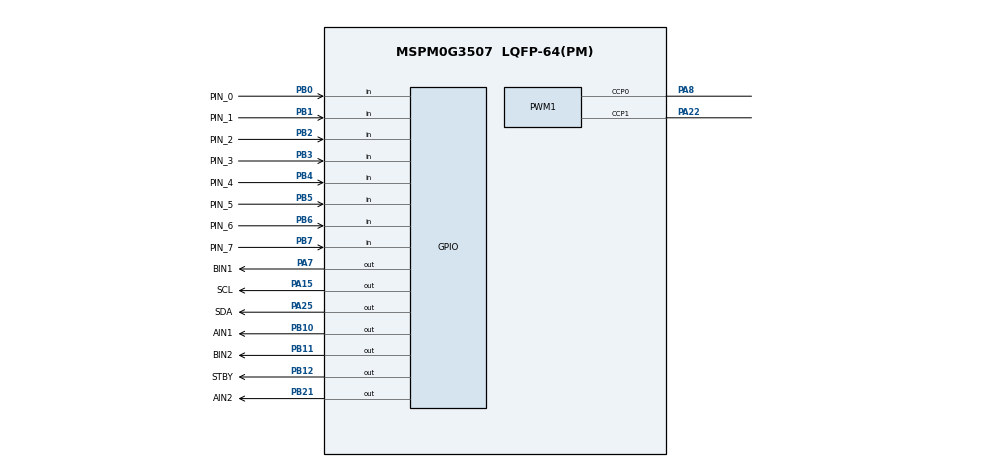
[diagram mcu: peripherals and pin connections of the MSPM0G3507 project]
/**
 * These arguments were used when this file was generated. They will be automatically applied on subsequent loads
 * via the GUI or CLI. Run CLI with '--help' for additional information on how to override these arguments.
 * @cliArgs --device "MSPM0G350X" --part "Default" --package "LQFP-64(PM)" --product "mspm0_sdk@2.08.00.03"
 * @v2CliArgs --device "MSPM0G3507" --package "LQFP-64(PM)" --product "mspm0_sdk@2.08.00.03"
 * @versions {"tool":"1.24.0+4110"}
 */

/**
 * Import the modules used in this configuration.
 */
const GPIO          = scripting.addModule("/ti/driverlib/GPIO", {}, false);
const GPIO1         = GPIO.addInstance();
const GPIO2         = GPIO.addInstance();
const GPIO3         = GPIO.addInstance();
const GPIO4         = GPIO.addInstance();
const GPIO5         = GPIO.addInstance();
const PWM           = scripting.addModule("/ti/driverlib/PWM", {}, false);
const PWM1          = PWM.addInstance();
const SYSCTL        = scripting.addModule("/ti/driverlib/SYSCTL");
const SYSTICK       = scripting.addModule("/ti/driverlib/SYSTICK");
const TIMER         = scripting.addModule("/ti/driverlib/TIMER", {}, false);
const TIMER1        = TIMER.addInstance();
const TIMER2        = TIMER.addInstance();
const ProjectConfig = scripting.addModule("/ti/project_config/ProjectConfig");

/**
 * Write custom configuration values to the imported modules.
 */
const divider7       = system.clockTree["PLL_PDIV"];
divider7.divideValue = 2;

const divider9       = system.clockTree["UDIV"];
divider9.divideValue = 2;

const gate7  = system.clockTree["MFCLKGATE"];
gate7.enable = true;

const multiplier2         = system.clockTree["PLL_QDIV"];
multiplier2.multiplyValue = 8;

const mux4       = system.clockTree["EXHFMUX"];
mux4.inputSelect = "EXHFMUX_XTAL";

const mux8       = system.clockTree["HSCLKMUX"];
mux8.inputSelect = "HSCLKMUX_SYSPLL0";

const mux12       = system.clockTree["SYSPLLMUX"];
mux12.inputSelect = "zSYSPLLMUX_HFCLK";

const pinFunction4        = system.clockTree["HFXT"];
pinFunction4.inputFreq    = 40;
pinFunction4.enable       = true;
pinFunction4.HFCLKMonitor = true;
pinFunction4.HFXTStartup  = 100;

GPIO1.$name                          = "OLED";
GPIO1.port                           = "PORTA";
GPIO1.associatedPins.create(2);
GPIO1.associatedPins[0].$name        = "SCL";
GPIO1.associatedPins[0].initialValue = "SET";
GPIO1.associatedPins[0].assignedPin  = "15";
GPIO1.associatedPins[0].ioStructure  = "SD";
GPIO1.associatedPins[0].pin.$assign  = "PA15";
GPIO1.associatedPins[1].$name        = "SDA";
GPIO1.associatedPins[1].initialValue = "SET";
GPIO1.associatedPins[1].assignedPin  = "25";
GPIO1.associatedPins[1].ioStructure  = "SD";
GPIO1.associatedPins[1].pin.$assign  = "PA25";

const Board = scripting.addModule("/ti/driverlib/Board", {}, false);

GPIO2.$name                              = "LS";
GPIO2.port                               = "PORTB";
GPIO2.associatedPins.create(8);
GPIO2.associatedPins[0].$name            = "PIN_0";
GPIO2.associatedPins[0].direction        = "INPUT";
GPIO2.associatedPins[0].internalResistor = "PULL_UP";
GPIO2.associatedPins[0].ioStructure      = "SD";
GPIO2.associatedPins[0].assignedPin      = "0";
GPIO2.associatedPins[0].pin.$assign      = "PB0";
GPIO2.associatedPins[1].$name            = "PIN_1";
GPIO2.associatedPins[1].direction        = "INPUT";
GPIO2.associatedPins[1].ioStructure      = "SD";
GPIO2.associatedPins[1].internalResistor = "PULL_UP";
GPIO2.associatedPins[1].assignedPin      = "1";
GPIO2.associatedPins[1].pin.$assign      = "PB1";
GPIO2.associatedPins[2].$name            = "PIN_2";
GPIO2.associatedPins[2].direction        = "INPUT";
GPIO2.associatedPins[2].ioStructure      = "SD";
GPIO2.associatedPins[2].internalResistor = "PULL_UP";
GPIO2.associatedPins[2].assignedPin      = "2";
GPIO2.associatedPins[2].pin.$assign      = "PB2";
GPIO2.associatedPins[3].$name            = "PIN_3";
GPIO2.associatedPins[3].direction        = "INPUT";
GPIO2.associatedPins[3].ioStructure      = "SD";
GPIO2.associatedPins[3].internalResistor = "PULL_UP";
GPIO2.associatedPins[3].assignedPin      = "3";
GPIO2.associatedPins[3].pin.$assign      = "PB3";
GPIO2.associatedPins[4].$name            = "PIN_4";
GPIO2.associatedPins[4].direction        = "INPUT";
GPIO2.associatedPins[4].ioStructure      = "SD";
GPIO2.associatedPins[4].internalResistor = "PULL_UP";
GPIO2.associatedPins[4].assignedPin      = "4";
GPIO2.associatedPins[4].pin.$assign      = "PB4";
GPIO2.associatedPins[5].$name            = "PIN_5";
GPIO2.associatedPins[5].direction        = "INPUT";
GPIO2.associatedPins[5].ioStructure      = "SD";
GPIO2.associatedPins[5].internalResistor = "PULL_UP";
GPIO2.associatedPins[5].assignedPin      = "5";
GPIO2.associatedPins[5].pin.$assign      = "PB5";
GPIO2.associatedPins[6].$name            = "PIN_6";
GPIO2.associatedPins[6].direction        = "INPUT";
GPIO2.associatedPins[6].ioStructure      = "SD";
GPIO2.associatedPins[6].internalResistor = "PULL_UP";
GPIO2.associatedPins[6].assignedPin      = "6";
GPIO2.associatedPins[6].pin.$assign      = "PB6";
GPIO2.associatedPins[7].$name            = "PIN_7";
GPIO2.associatedPins[7].direction        = "INPUT";
GPIO2.associatedPins[7].ioStructure      = "SD";
GPIO2.associatedPins[7].internalResistor = "PULL_UP";
GPIO2.associatedPins[7].assignedPin      = "7";
GPIO2.associatedPins[7].pin.$assign      = "PB7";

GPIO3.$name                              = "PWM";
GPIO3.associatedPins.create(5);
GPIO3.associatedPins[0].$name            = "AIN1";
GPIO3.associatedPins[0].ioStructure      = "SD";
GPIO3.associatedPins[0].pin.$assign      = "PB10";
GPIO3.associatedPins[1].$name            = "AIN2";
GPIO3.associatedPins[1].ioStructure      = "SD";
GPIO3.associatedPins[1].pin.$assign      = "PB21";
GPIO3.associatedPins[2].$name            = "BIN1";
GPIO3.associatedPins[2].ioStructure      = "SD";
GPIO3.associatedPins[2].pin.$assign      = "PA7";
GPIO3.associatedPins[3].$name            = "BIN2";
GPIO3.associatedPins[3].ioStructure      = "SD";
GPIO3.associatedPins[3].pin.$assign      = "PB11";
GPIO3.associatedPins[4].$name            = "STBY";
GPIO3.associatedPins[4].ioStructure      = "SD";
GPIO3.associatedPins[4].internalResistor = "PULL_UP";
GPIO3.associatedPins[4].pin.$assign      = "PB12";

GPIO4.$name                               = "GPIO_ENCODER_L";
GPIO4.associatedPins.create(2);
GPIO4.associatedPins[0].direction         = "INPUT";
GPIO4.associatedPins[0].polarity          = "RISE";
GPIO4.associatedPins[0].interruptPriority = "0";
GPIO4.associatedPins[0].assignedPort      = "PORTA";
GPIO4.associatedPins[0].$name             = "E1A";
GPIO4.associatedPins[0].assignedPin       = "12";
GPIO4.associatedPins[1].direction         = "INPUT";
GPIO4.associatedPins[1].assignedPort      = "PORTB";
GPIO4.associatedPins[1].assignedPin       = "22";
GPIO4.associatedPins[1].polarity          = "RISE";
GPIO4.associatedPins[1].interruptEn       = true;
GPIO4.associatedPins[1].interruptPriority = "0";
GPIO4.associatedPins[1].$name             = "E1B";

GPIO5.$name                               = "GPIO_ENCODER_R";
GPIO5.associatedPins.create(2);
GPIO5.associatedPins[0].direction         = "INPUT";
GPIO5.associatedPins[0].assignedPort      = "PORTB";
GPIO5.associatedPins[0].assignedPin       = "13";
GPIO5.associatedPins[0].polarity          = "RISE";
GPIO5.associatedPins[0].interruptEn       = true;
GPIO5.associatedPins[0].interruptPriority = "0";
GPIO5.associatedPins[0].$name             = "E2A";
GPIO5.associatedPins[1].direction         = "INPUT";
GPIO5.associatedPins[1].assignedPort      = "PORTA";
GPIO5.associatedPins[1].assignedPin       = "31";
GPIO5.associatedPins[1].polarity          = "RISE";
GPIO5.associatedPins[1].interruptPriority = "0";
GPIO5.associatedPins[1].$name             = "E2B";

PWM1.$name                              = "motorPWM";
PWM1.pwmMode                            = "EDGE_ALIGN_UP";
PWM1.peripheral.$assign                 = "TIMA0";
PWM1.peripheral.ccp0Pin.$assign         = "PA8";
PWM1.peripheral.ccp1Pin.$assign         = "PA22";
PWM1.PWM_CHANNEL_0.$name                = "ti_driverlib_pwm_PWMTimerCC0";
PWM1.PWM_CHANNEL_1.$name                = "ti_driverlib_pwm_PWMTimerCC1";
PWM1.ccp0PinConfig.$name                = "ti_driverlib_gpio_GPIOPinGeneric0";
PWM1.ccp0PinConfig.direction            = scripting.forceWrite("OUTPUT");
PWM1.ccp0PinConfig.hideOutputInversion  = scripting.forceWrite(false);
PWM1.ccp0PinConfig.onlyInternalResistor = scripting.forceWrite(false);
PWM1.ccp0PinConfig.passedPeripheralType = scripting.forceWrite("Digital");
PWM1.ccp1PinConfig.$name                = "ti_driverlib_gpio_GPIOPinGeneric1";
PWM1.ccp1PinConfig.direction            = scripting.forceWrite("OUTPUT");
PWM1.ccp1PinConfig.hideOutputInversion  = scripting.forceWrite(false);
PWM1.ccp1PinConfig.onlyInternalResistor = scripting.forceWrite(false);
PWM1.ccp1PinConfig.passedPeripheralType = scripting.forceWrite("Digital");

SYSCTL.forceDefaultClkConfig = true;
SYSCTL.clockTreeEn           = true;
SYSCTL.validateClkStatus     = true;

SYSTICK.periodEnable      = true;
SYSTICK.systickEnable     = true;
SYSTICK.interruptPriority = "0";
SYSTICK.period            = 80;

TIMER1.$name              = "TIMER_10ms";
TIMER1.timerMode          = "PERIODIC";
TIMER1.timerStartTimer    = true;
TIMER1.interrupts         = ["ZERO"];
TIMER1.interruptPriority  = "3";
TIMER1.timerPeriod        = "10 ms";
TIMER1.timerClkPrescale   = 10;
TIMER1.timerClkDiv        = 8;
TIMER1.peripheral.$assign = "TIMG8";

TIMER2.$name              = "PIDloop";
TIMER2.timerMode          = "PERIODIC";
TIMER2.timerStartTimer    = true;
TIMER2.interrupts         = ["ZERO"];
TIMER2.interruptPriority  = "3";
TIMER2.timerClkPrescale   = 10;
TIMER2.timerClkDiv        = 8;
TIMER2.timerPeriod        = "20 ms";
TIMER2.peripheral.$assign = "TIMG6";

/**
 * Pinmux solution for unlocked pins/peripherals. This ensures that minor changes to the automatic solver in a future
 * version of the tool will not impact the pinmux you originally saw.  These lines can be completely deleted in order to
 * re-solve from scratch.
 */
pinFunction4.peripheral.$suggestSolution           = "SYSCTL";
pinFunction4.peripheral.hfxInPin.$suggestSolution  = "PA5";
pinFunction4.peripheral.hfxOutPin.$suggestSolution = "PA6";
Board.peripheral.$suggestSolution                  = "DEBUGSS";
Board.peripheral.swclkPin.$suggestSolution         = "PA20";
Board.peripheral.swdioPin.$suggestSolution         = "PA19";
GPIO4.associatedPins[0].pin.$suggestSolution       = "PA12";
GPIO4.associatedPins[1].pin.$suggestSolution       = "PB22";
GPIO5.associatedPins[0].pin.$suggestSolution       = "PB13";
GPIO5.associatedPins[1].pin.$suggestSolution       = "PA31";
